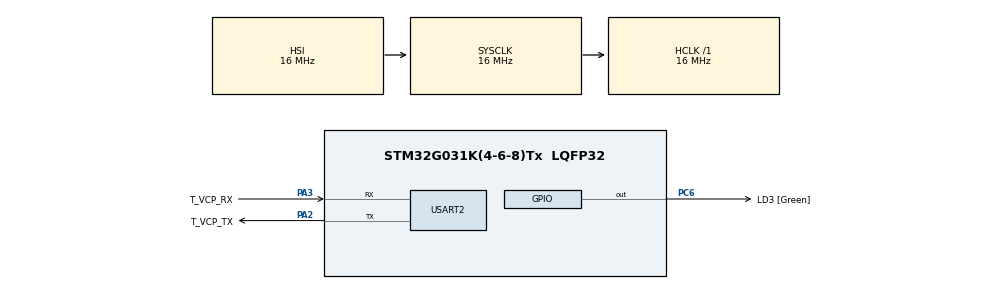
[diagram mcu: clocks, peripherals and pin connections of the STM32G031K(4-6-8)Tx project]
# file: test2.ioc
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Dma.Request0=USART2_TX
Dma.USART2_TX.0.Direction=DMA_MEMORY_TO_PERIPH
Dma.USART2_TX.0.EventEnable=DISABLE
Dma.USART2_TX.0.Instance=DMA1_Channel1
Dma.USART2_TX.0.MemDataAlignment=DMA_MDATAALIGN_BYTE
Dma.USART2_TX.0.MemInc=DMA_MINC_ENABLE
Dma.USART2_TX.0.Mode=DMA_NORMAL
Dma.USART2_TX.0.PeriphDataAlignment=DMA_PDATAALIGN_BYTE
Dma.USART2_TX.0.PeriphInc=DMA_PINC_DISABLE
Dma.USART2_TX.0.Polarity=HAL_DMAMUX_REQ_GEN_RISING
Dma.USART2_TX.0.Priority=DMA_PRIORITY_LOW
Dma.USART2_TX.0.RequestNumber=1
Dma.USART2_TX.0.SignalID=NONE
Dma.USART2_TX.0.SyncEnable=DISABLE
Dma.USART2_TX.0.SyncPolarity=HAL_DMAMUX_SYNC_NO_EVENT
Dma.USART2_TX.0.SyncRequestNumber=1
Dma.USART2_TX.0.SyncSignalID=NONE
Mcu.Family=STM32G0
Mcu.Name=STM32G031K(4-6-8)Tx
Mcu.Package=LQFP32
NVIC.DMA1_Channel1_IRQn=true\:0\:0\:false\:false\:true\:false\:true\:true
NVIC.USART2_IRQn=true\:0\:0\:false\:false\:true\:true\:true\:true
PA2.GPIO_Label=T_VCP_TX
PA2.GPIO_PuPd=GPIO_PULLUP
PA2.Mode=Asynchronous
PA2.Signal=USART2_TX
PA3.GPIO_Label=T_VCP_RX
PA3.GPIO_PuPd=GPIO_PULLUP
PA3.Mode=Asynchronous
PA3.Signal=USART2_RX
PC6.GPIO_Label=LD3 [Green]
PC6.Signal=GPIO_Output
ProjectManager.HeapSize=0x200
ProjectManager.StackSize=0x400
ProjectManager.TargetToolchain=STM32CubeIDE
RCC.AHBFreq_Value=16000000
RCC.CortexFreq_Value=16000000
RCC.EXTERNAL_CLOCK_VALUE=12288000
RCC.HCLKFreq_Value=16000000
RCC.HSE_VALUE=8000000
RCC.HSI_VALUE=16000000
RCC.SYSCLKFreq_VALUE=16000000
RCC.VCOOutputFreq_Value=128000000
USART2.VirtualMode-Asynchronous=VM_ASYNC
USART2.WordLength=WORDLENGTH_8B
board=NUCLEO-G031K8

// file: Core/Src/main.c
/* USER CODE BEGIN Header */
/**
  ******************************************************************************
  * @file           : main.c
  * @brief          : Main program body
  ******************************************************************************
  * @attention
  *
  * Copyright (c) 2026 STMicroelectronics.
  * All rights reserved.
  *
  * This software is licensed under terms that can be found in the LICENSE file
  * in the root directory of this software component.
  * If no LICENSE file comes with this software, it is provided AS-IS.
  *
  ******************************************************************************
  */
/* USER CODE END Header */
#include "main.h"

UART_HandleTypeDef huart2;
DMA_HandleTypeDef hdma_usart2_tx;

/* USER CODE BEGIN PV */
typedef enum {WAIT_HEAD, WAIT_CMD, WAIT_LEN, WAIT_PAYLOAD, WAIT_CHK, WAIT_STOP} PktState;
PktState state = WAIT_HEAD;
uint8_t rx_byte;
uint8_t cmd, len, payload[32], idx, checksum;
uint8_t reply[36];
/* USER CODE END PV */

void SystemClock_Config(void);
static void MX_GPIO_Init(void);
static void MX_DMA_Init(void);
static void MX_USART2_UART_Init(void);

int main(void)
{

  /* MCU Configuration--------------------------------------------------------*/

  /* Reset of all peripherals, Initializes the Flash interface and the Systick. */
  HAL_Init();

  /* Configure the system clock */
  SystemClock_Config();

  /* Initialize all configured peripherals */
  MX_GPIO_Init();
  MX_DMA_Init();
  MX_USART2_UART_Init();
  /* USER CODE BEGIN 2 */
  HAL_UART_Receive_IT(&huart2, &rx_byte, 1);
  /* USER CODE END 2 */

  /* Infinite loop */
  while (1)
  {

  }
}

void SystemClock_Config(void)
{
  RCC_OscInitTypeDef RCC_OscInitStruct = {0};
  RCC_ClkInitTypeDef RCC_ClkInitStruct = {0};

  /** Configure the main internal regulator output voltage
  */
  HAL_PWREx_ControlVoltageScaling(PWR_REGULATOR_VOLTAGE_SCALE1);

  /** Initializes the RCC Oscillators according to the specified parameters
  * in the RCC_OscInitTypeDef structure.
  */
  RCC_OscInitStruct.OscillatorType = RCC_OSCILLATORTYPE_HSI;
  RCC_OscInitStruct.HSIState = RCC_HSI_ON;
  RCC_OscInitStruct.HSIDiv = RCC_HSI_DIV1;
  RCC_OscInitStruct.HSICalibrationValue = RCC_HSICALIBRATION_DEFAULT;
  RCC_OscInitStruct.PLL.PLLState = RCC_PLL_NONE;
  if (HAL_RCC_OscConfig(&RCC_OscInitStruct) != HAL_OK)
  {
    Error_Handler();
  }

  /** Initializes the CPU, AHB and APB buses clocks
  */
  RCC_ClkInitStruct.ClockType = RCC_CLOCKTYPE_HCLK|RCC_CLOCKTYPE_SYSCLK
                              |RCC_CLOCKTYPE_PCLK1;
  RCC_ClkInitStruct.SYSCLKSource = RCC_SYSCLKSOURCE_HSI;
  RCC_ClkInitStruct.AHBCLKDivider = RCC_SYSCLK_DIV1;
  RCC_ClkInitStruct.APB1CLKDivider = RCC_HCLK_DIV1;

  if (HAL_RCC_ClockConfig(&RCC_ClkInitStruct, FLASH_LATENCY_0) != HAL_OK)
  {
    Error_Handler();
  }
}

static void MX_USART2_UART_Init(void)
{

  huart2.Instance = USART2;
  huart2.Init.BaudRate = 115200;
  huart2.Init.WordLength = UART_WORDLENGTH_8B;
  huart2.Init.StopBits = UART_STOPBITS_1;
  huart2.Init.Parity = UART_PARITY_NONE;
  huart2.Init.Mode = UART_MODE_TX_RX;
  huart2.Init.HwFlowCtl = UART_HWCONTROL_NONE;
  huart2.Init.OverSampling = UART_OVERSAMPLING_16;
  huart2.Init.OneBitSampling = UART_ONE_BIT_SAMPLE_DISABLE;
  huart2.Init.ClockPrescaler = UART_PRESCALER_DIV1;
  huart2.AdvancedInit.AdvFeatureInit = UART_ADVFEATURE_NO_INIT;
  if (HAL_UART_Init(&huart2) != HAL_OK)
  {
    Error_Handler();
  }

}

static void MX_DMA_Init(void)
{

  /* DMA controller clock enable */
  __HAL_RCC_DMA1_CLK_ENABLE();

  /* DMA interrupt init */
  /* DMA1_Channel1_IRQn interrupt configuration */
  HAL_NVIC_SetPriority(DMA1_Channel1_IRQn, 0, 0);
  HAL_NVIC_EnableIRQ(DMA1_Channel1_IRQn);

}

static void MX_GPIO_Init(void)
{
  GPIO_InitTypeDef GPIO_InitStruct = {0};

  /* GPIO Ports Clock Enable */
  __HAL_RCC_GPIOA_CLK_ENABLE();
  __HAL_RCC_GPIOC_CLK_ENABLE();

  /*Configure GPIO pin Output Level */
  HAL_GPIO_WritePin(LD3_GPIO_Port, LD3_Pin, GPIO_PIN_RESET);

  /*Configure GPIO pin : LD3_Pin */
  GPIO_InitStruct.Pin = LD3_Pin;
  GPIO_InitStruct.Mode = GPIO_MODE_OUTPUT_PP;
  GPIO_InitStruct.Pull = GPIO_NOPULL;
  GPIO_InitStruct.Speed = GPIO_SPEED_FREQ_LOW;
  HAL_GPIO_Init(LD3_GPIO_Port, &GPIO_InitStruct);

}

/* USER CODE BEGIN 4 */
void HAL_UART_RxCpltCallback(UART_HandleTypeDef *huart)
{
  if (huart->Instance == USART2)
  {
    switch (state)
    {
      case WAIT_HEAD:
        if (rx_byte == 0xAA) state = WAIT_CMD;
        break;

      case WAIT_CMD:
        cmd = rx_byte;
        checksum = rx_byte;
        state = WAIT_LEN;
        break;

      case WAIT_LEN:
        len = rx_byte;
        if (len > 0x20) { state = WAIT_HEAD; break; }
        checksum ^= rx_byte;
        idx = 0;
        state = (len == 0) ? WAIT_CHK : WAIT_PAYLOAD;
        break;

      case WAIT_PAYLOAD:
        payload[idx++] = rx_byte;
        checksum ^= rx_byte;
        if (idx == len) state = WAIT_CHK;
        break;

      case WAIT_CHK:
        state = (rx_byte == checksum) ? WAIT_STOP : WAIT_HEAD;
        break;

      case WAIT_STOP:
        if (rx_byte == 0x00)
        {
          uint8_t ridx = 0;
          reply[ridx++] = 0xAA;
          reply[ridx++] = cmd;
          reply[ridx++] = len;
          uint8_t reply_chk = cmd ^ len;
          for (uint8_t i = 0; i < len; i++)
          {
            reply[ridx++] = payload[i];
            reply_chk ^= payload[i];
          }
          reply[ridx++] = reply_chk;
          reply[ridx++] = 0x00;
          HAL_UART_Transmit_DMA(&huart2, reply, ridx);
        }
        state = WAIT_HEAD;
        break;
    }
    HAL_UART_Receive_IT(huart, &rx_byte, 1);
  }
}
void HAL_UART_TxCpltCallback(UART_HandleTypeDef *huart)
{
  if (huart->Instance == USART2)
  {
  }
}
/* USER CODE END 4 */

void Error_Handler(void)
{
  __disable_irq();
  while (1)
  {
  }
}
